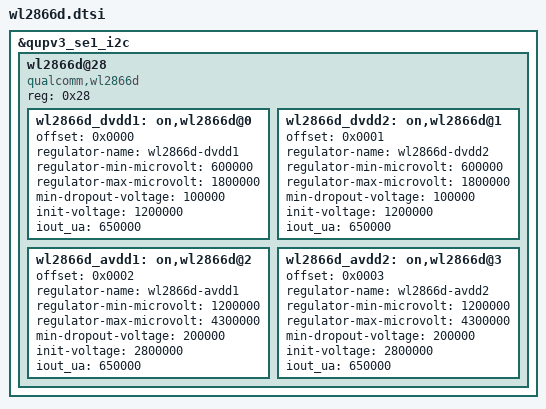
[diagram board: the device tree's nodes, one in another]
&qupv3_se1_i2c {
    #address-cells = <1>;
    #size-cells = <0>;
    status = "ok";
    wl2866d@28{
        compatible = "qualcomm,wl2866d";
        reg = <0x28>;
        status = "ok";

        wl2866d_dvdd1:on,wl2866d@0{
            offset = /bits/ 16 <0x0000>;
            regulator-name ="wl2866d-dvdd1";
            regulator-min-microvolt = <600000>;
            regulator-max-microvolt = <1800000>;
            min-dropout-voltage = <100000>;
            init-voltage = <1200000>;
            iout_ua = <650000>;
        };

        wl2866d_dvdd2:on,wl2866d@1{
            offset = /bits/ 16 <0x0001>;
            regulator-name ="wl2866d-dvdd2";
            regulator-min-microvolt = <600000>;
            regulator-max-microvolt = <1800000>;
            min-dropout-voltage = <100000>;
            init-voltage = <1200000>;
            iout_ua = <650000>;
        };

        wl2866d_avdd1:on,wl2866d@2{
            offset = /bits/ 16 <0x0002>;
            regulator-name ="wl2866d-avdd1";
            regulator-min-microvolt = <1200000>;
            regulator-max-microvolt = <4300000>;
            min-dropout-voltage = <200000>;
            init-voltage = <2800000>;
            iout_ua = <650000>;
        };

        wl2866d_avdd2:on,wl2866d@3{
            offset = /bits/ 16 <0x0003>;
            regulator-name ="wl2866d-avdd2";
            regulator-min-microvolt = <1200000>;
            regulator-max-microvolt = <4300000>;
            min-dropout-voltage = <200000>;
            init-voltage = <2800000>;
            iout_ua = <650000>;
        };
    };
};
